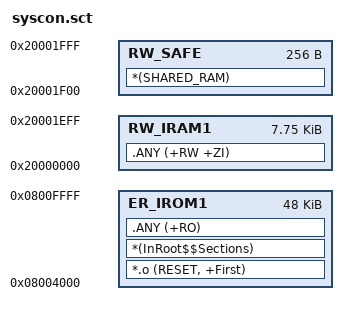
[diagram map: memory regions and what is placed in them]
; *************************************************************
; *** Scatter-Loading Description File generated by uVision ***
; *************************************************************

LR_IROM1 0x08004000 0x0000C000  {    ; load region size_region
  ER_IROM1 0x08004000 0x0000C000  {  ; load address = execution address
   *.o (RESET, +First)
   *(InRoot$$Sections)
   .ANY (+RO)
  }
  RW_IRAM1 0x20000000 0x00001F00  {  ; RW data
   .ANY (+RW +ZI)
  }
  RW_SAFE 0x20001F00 0x00000100  {  ; RW data
   *(SHARED_RAM)
  }
}
